# PIC32MX460F256L register map
Vendor: Microchip
Registers are 32-bit, read-write, reset 0x0 unless marked. A register's access mark holds for its fields unless they carry their own. Addresses are absolute, and some are shared; only a register's first bit layout is shown; [hi:lo] are bit positions; {n}, {i} and the like mark numbered series.

## _APPO
0x1F880180 _APPO reset not defined — George (power-on value xxxxxxxxxxxxxxxxxxxxxxxxxxxxxxxx)

## _APPI
0x1F880190 _APPI reset not defined — George (power-on value xxxxxxxxxxxxxxxxxxxxxxxxxxxxxxxx)

## INT
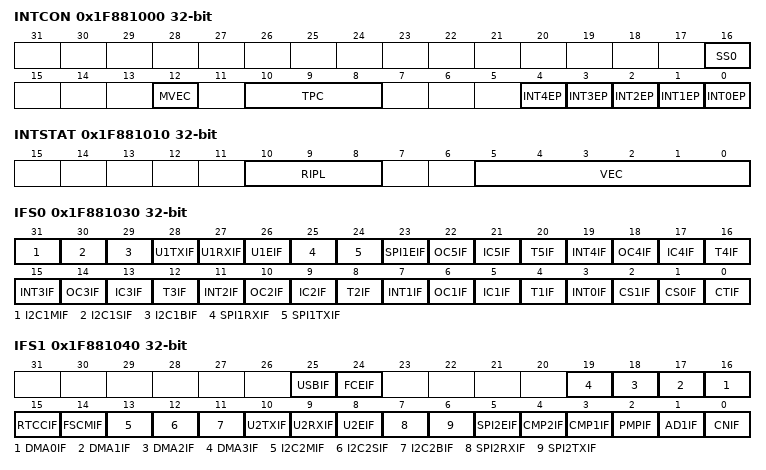
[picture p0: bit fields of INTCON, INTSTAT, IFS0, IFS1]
0x1F881000 INTCON
  [16] SS0, [12] MVEC, [10:8] TPC, [n] INT{n}EP (n=0..4)
0x1F881010 INTSTAT
  [10:8] RIPL, [5:0] VEC
0x1F881020 IPTMR
0x1F881030 IFS0
  [31] I2C1MIF, [30] I2C1SIF, [29] I2C1BIF, [28] U1TXIF, [27] U1RXIF, [26] U1EIF, [25] SPI1RXIF, [24] SPI1TXIF, [23] SPI1EIF, [4n+2] OC{n}IF (n=1..5), [4n+1] IC{n}IF (n=1..5), [4n] T{n}IF (n=1..5), [4n+3] INT{n}IF (n=0..4), [2] CS1IF, [1] CS0IF, [0] CTIF
0x1F881040 IFS1
  [25] USBIF, [24] FCEIF, [n+16] DMA{n}IF (n=0..3), [15] RTCCIF, [14] FSCMIF, [13] I2C2MIF, [12] I2C2SIF, [11] I2C2BIF, [10] U2TXIF, [9] U2RXIF, [8] U2EIF, [7] SPI2RXIF, [6] SPI2TXIF, [5] SPI2EIF, [4] CMP2IF, [3] CMP1IF, [2] PMPIF, [1] AD1IF, [0] CNIF
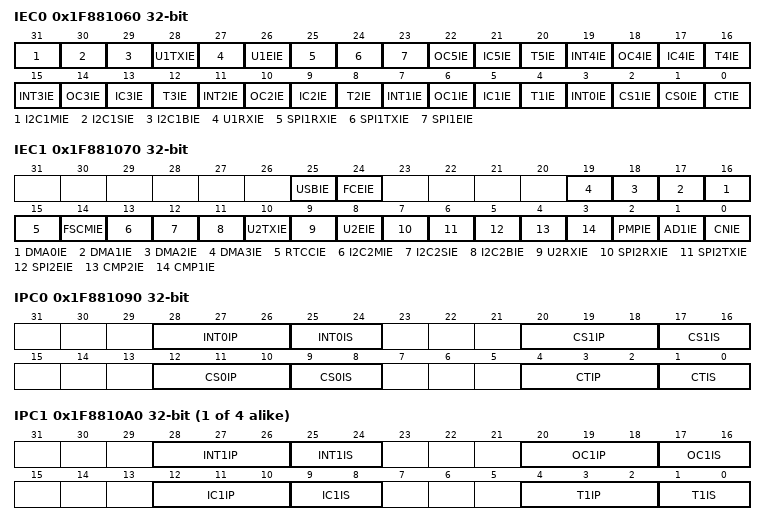
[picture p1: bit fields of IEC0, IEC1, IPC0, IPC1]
0x1F881060 IEC0
  [31] I2C1MIE, [30] I2C1SIE, [29] I2C1BIE, [28] U1TXIE, [27] U1RXIE, [26] U1EIE, [25] SPI1RXIE, [24] SPI1TXIE, [23] SPI1EIE, [4n+2] OC{n}IE (n=1..5), [4n+1] IC{n}IE (n=1..5), [4n] T{n}IE (n=1..5), [4n+3] INT{n}IE (n=0..4), [2] CS1IE, [1] CS0IE, [0] CTIE
0x1F881070 IEC1
  [25] USBIE, [24] FCEIE, [n+16] DMA{n}IE (n=0..3), [15] RTCCIE, [14] FSCMIE, [13] I2C2MIE, [12] I2C2SIE, [11] I2C2BIE, [10] U2TXIE, [9] U2RXIE, [8] U2EIE, [7] SPI2RXIE, [6] SPI2TXIE, [5] SPI2EIE, [4] CMP2IE, [3] CMP1IE, [2] PMPIE, [1] AD1IE, [0] CNIE
0x1F881090 IPC0
  [28:26] INT0IP, [25:24] INT0IS, [20:18] CS1IP, [17:16] CS1IS, [12:10] CS0IP, [9:8] CS0IS, [4:2] CTIP, [1:0] CTIS
{0x1F881090+0x10*i} IPC{i} (i=1..4)
  [28:26] INT{i}IP, [25:24] INT{i}IS, [20:18] OC{i}IP, [17:16] OC{i}IS, [12:10] IC{i}IP, [9:8] IC{i}IS, [4:2] T{i}IP, [1:0] T{i}IS
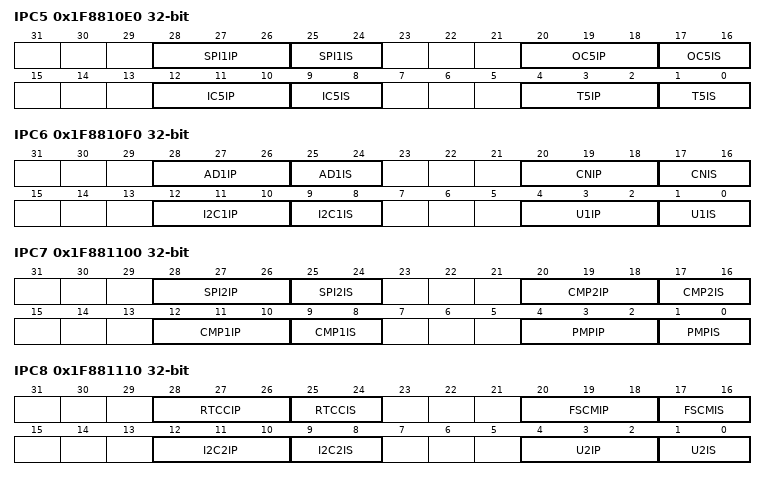
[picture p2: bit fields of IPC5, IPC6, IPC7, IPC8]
0x1F8810E0 IPC5
  [28:26] SPI1IP, [25:24] SPI1IS, [20:18] OC5IP, [17:16] OC5IS, [12:10] IC5IP, [9:8] IC5IS, [4:2] T5IP, [1:0] T5IS
0x1F8810F0 IPC6
  [28:26] AD1IP, [25:24] AD1IS, [20:18] CNIP, [17:16] CNIS, [12:10] I2C1IP, [9:8] I2C1IS, [4:2] U1IP, [1:0] U1IS
0x1F881100 IPC7
  [28:26] SPI2IP, [25:24] SPI2IS, [20:18] CMP2IP, [17:16] CMP2IS, [12:10] CMP1IP, [9:8] CMP1IS, [4:2] PMPIP, [1:0] PMPIS
0x1F881110 IPC8
  [28:26] RTCCIP, [25:24] RTCCIS, [20:18] FSCMIP, [17:16] FSCMIS, [12:10] I2C2IP, [9:8] I2C2IS, [4:2] U2IP, [1:0] U2IS
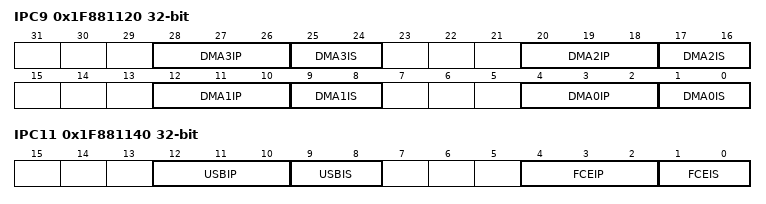
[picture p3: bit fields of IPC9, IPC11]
0x1F881120 IPC9
  [8n+4:8n+2] DMA{n}IP (n=0..3), [8n+1:8n] DMA{n}IS (n=0..3)
0x1F881140 IPC11
  [12:10] USBIP, [9:8] USBIS, [4:2] FCEIP, [1:0] FCEIS

## BMX
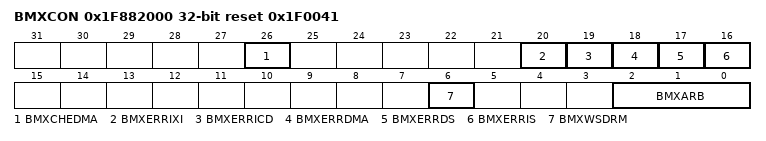
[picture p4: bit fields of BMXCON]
0x1F882000 BMXCON reset 0x1F0041
  [26] BMXCHEDMA, [20] BMXERRIXI, [19] BMXERRICD, [18] BMXERRDMA, [17] BMXERRDS, [16] BMXERRIS, [6] BMXWSDRM, [2:0] BMXARB
0x1F882010 BMXDKPBA
0x1F882020 BMXDUDBA
0x1F882030 BMXDUPBA
0x1F882040 BMXDRMSZ ro reset 0x20000
0x1F882050 BMXPUPBA
0x1F882060 BMXPFMSZ ro reset 0x80000
0x1F882070 BMXBOOTSZ ro reset 0x3000

## dma_bvci
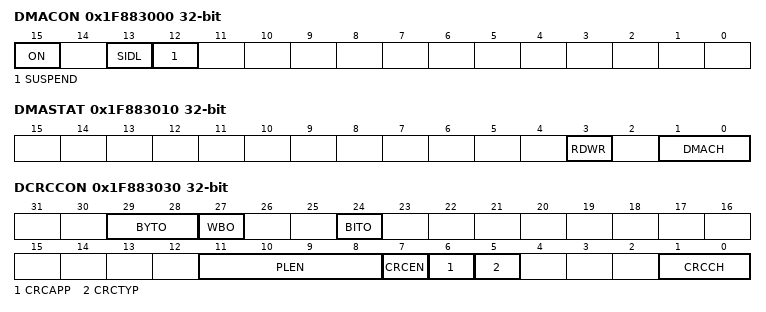
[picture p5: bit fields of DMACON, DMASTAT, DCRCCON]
0x1F883000 DMACON reset not defined — (power-on value ----------------00x0------------)
  [15] ON, [13] SIDL, [12] SUSPEND
0x1F883010 DMASTAT reset not defined — (power-on value ----------------------------0-xx)
  [3] RDWR, [1:0] DMACH
0x1F883020 DMAADDR ro
0x1F883030 DCRCCON reset not defined — (power-on value --xxx--x------------xxxx00x---xx)
  [29:28] BYTO, [27] WBO, [24] BITO, [11:8] PLEN, [7] CRCEN, [6] CRCAPP, [5] CRCTYP, [1:0] CRCCH
0x1F883040 DCRCDATA
0x1F883050 DCRCXOR

## DMAC0
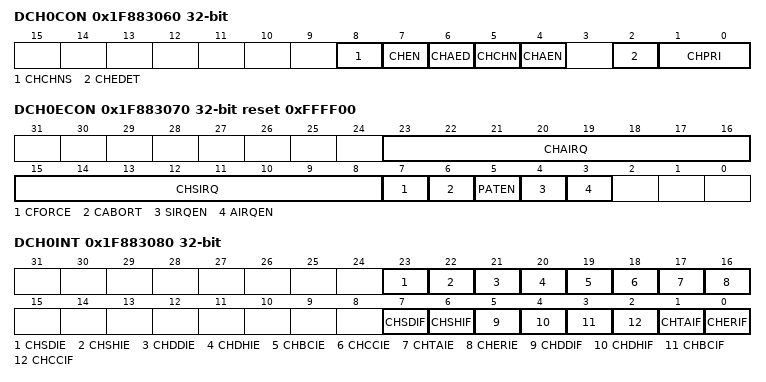
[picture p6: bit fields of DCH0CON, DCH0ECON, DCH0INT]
0x1F883060 DCH0CON
  [8] CHCHNS, [7] CHEN, [6] CHAED, [5] CHCHN, [4] CHAEN, [2] CHEDET ro, [1:0] CHPRI
0x1F883070 DCH0ECON reset 0xFFFF00
  [23:16] CHAIRQ
  [15:8] CHSIRQ
  [7] CFORCE — (can only be set)
  [6] CABORT — (can only be set)
  [5] PATEN
  [4] SIRQEN
  [3] AIRQEN
0x1F883080 DCH0INT
  [23] CHSDIE, [22] CHSHIE, [21] CHDDIE, [20] CHDHIE, [19] CHBCIE, [18] CHCCIE, [17] CHTAIE, [16] CHERIE, [7] CHSDIF, [6] CHSHIF, [5] CHDDIF, [4] CHDHIF, [3] CHBCIF, [2] CHCCIF, [1] CHTAIF, [0] CHERIF
0x1F883090 DCH0SSA reset not defined — (power-on value xxxxxxxxxxxxxxxxxxxxxxxxxxxxxxxx)
0x1F8830A0 DCH0DSA reset not defined — (power-on value xxxxxxxxxxxxxxxxxxxxxxxxxxxxxxxx)
0x1F8830B0 DCH0SSIZ reset not defined — (power-on value ----------------xxxxxxxxxxxxxxxx)
  [15:0] CHSSIZ
0x1F8830C0 DCH0DSIZ reset not defined — (power-on value ----------------xxxxxxxxxxxxxxxx)
  [15:0] CHDSIZ
0x1F8830D0 DCH0SPTR reset not defined — (power-on value ----------------xxxxxxxxxxxxxxxx)
  [15:0] CHSPTR
0x1F8830E0 DCH0DPTR ro
  [15:0] CHDPTR
0x1F8830F0 DCH0CSIZ reset not defined — (power-on value ----------------xxxxxxxxxxxxxxxx)
  [15:0] CHCSIZ
0x1F883100 DCH0CPTR reset not defined — (power-on value ----------------xxxxxxxxxxxxxxxx)
  [15:0] CHCPTR
0x1F883110 DCH0DAT reset not defined — (power-on value ------------------------xxxxxxxx)
  [7:0] DCHPDAT
